# ATSAMRH71F20C register map
Vendor: Microchip Technology; Series: SAMRH71; File version: 0
CPU: CM7 r1p1, little endian, MPU, FPU, double-precision FPU, I-cache, D-cache, ITCM, DTCM, 3 interrupt priority bits, 75 interrupts
Registers are 32-bit, read-write, reset 0x0 unless marked. A register's access mark holds for its fields unless they carry their own. Offsets are from the block's base; [hi:lo] are bit positions; {n}, {i} and the like mark numbered series; 'fields as' and 'values as' point back to an identical list.

## HEMC
Base 0x40080000
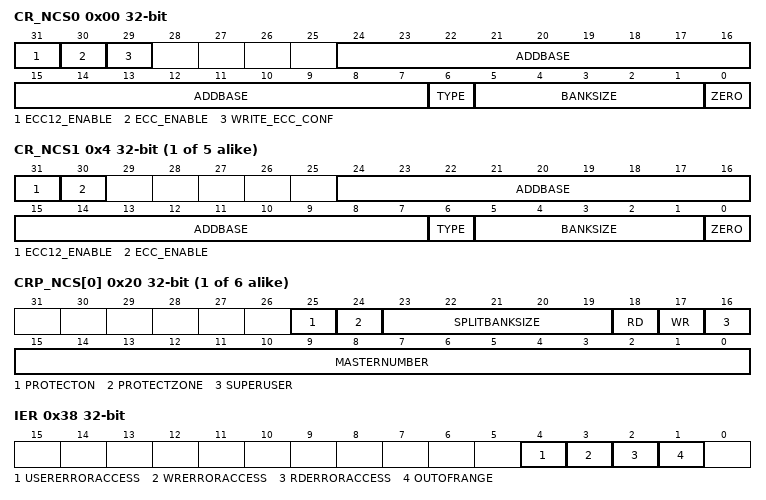
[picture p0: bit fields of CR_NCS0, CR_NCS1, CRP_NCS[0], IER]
0x00 CR_NCS0 — HEMC Control Register NCS 0
  [31] ECC12_ENABLE — BCH ECC Enable
  [30] ECC_ENABLE — ECC Protection Enable
  [29] WRITE_ECC_CONF — ECC Configuration Protection Enable
  [24:7] ADDBASE — relative base address of NCS area
  [6] TYPE — type of memory used
  [5:1] BANKSIZE
    0=_8KB (8Kbytes); 1=_16KB (16Kbytes); 2=_32KB (32Kbytes); 3=_64KB (64Kbytes); 4=_128KB (128Kbytes); 5=_256KB (256Kbytes); 6=_512KB (512Kbytes); 7=_1MB (1Mbytes); 8=_2MB (2Mbytes); 9=_4MB (4Mbytes); 10=_8MB (8Mbytes); 11=_16MB (16Mbytes); 12=_32MB (32Mbytes); 13=_64MB (64Mbytes); 14=_128MB (128Mbytes); 15=_256MB (256Mbytes (Default)); 16=_512MB (512Mbytes); 31=NOT_USED
  [0] ZERO — fixed to 0
{0x0+4i} CR_NCS{i} (i=1..5) — HEMC Control Register NCS {i}
  [31] ECC12_ENABLE — BCH ECC Enable
  [30] ECC_ENABLE — ECC Protection Enable
  [24:7] ADDBASE — relative base address of NCS area
  [6] TYPE — type of memory used
  [5:1] BANKSIZE
    values as CR_NCS0.BANKSIZE
  [0] ZERO — fixed to 0
0x18 CTRL — HEMC Polarity Control register
  [0] POL — External control buffer active polarity
{0x20+4i} CRP_NCS[{i}] (i=0..5) — HEMC Control Register Protection NCS
  [25] PROTECTON — protection activation
  [24] PROTECTZONE — select area protected
  [23:19] SPLITBANKSIZE — bank size internal separation
  [18] RD — Read Access
  [17] WR — Write Access
  [16] SUPERUSER — User or Superuser access
  [15:0] MASTERNUMBER — Master Number ID
0x38 IER wo — HEMC Interrupt Enable Register
  [4] USERERRORACCESS — user or superuser access error
  [3] WRERRORACCESS — write access error
  [2] RDERRORACCESS — read access error
  [1] OUTOFRANGE
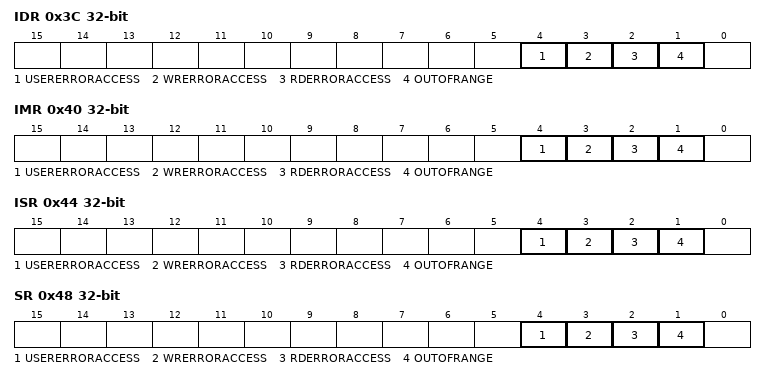
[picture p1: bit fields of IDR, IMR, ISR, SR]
0x3C IDR wo — HEMC Interrupt Disable Register
  fields as IER
0x40 IMR ro — HEMC Interrupt Mask Register
  fields as IER
0x44 ISR ro — HEMC Interrupt Status Register
  [4] USERERRORACCESS — User or SuperUser Error Access
  [3] WRERRORACCESS — Write access error
  [2] RDERRORACCESS — read access error
  [1] OUTOFRANGE
0x48 SR ro — HEMC Status Register
  [4] USERERRORACCESS — User or SuperUser Error Access
  [3] WRERRORACCESS — Write access error
  [2] RDERRORACCESS — Read access error
  [1] OUTOFRANGE
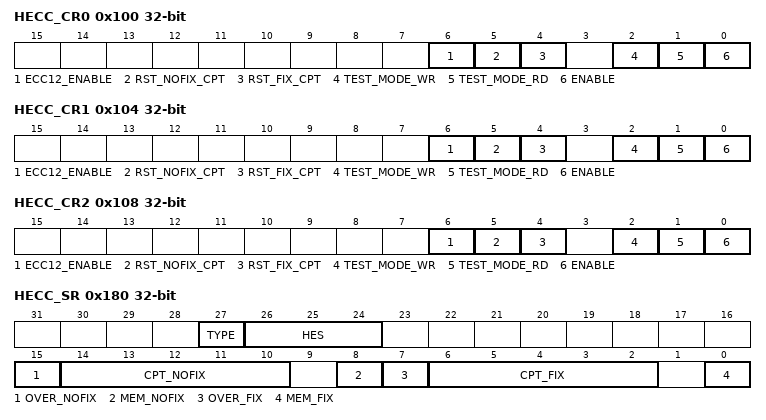
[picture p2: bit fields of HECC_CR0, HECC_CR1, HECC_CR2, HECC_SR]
0x100 HECC_CR0 — HECC Control Register Channel 0 (HSMC)
  [6] ECC12_ENABLE — BCH ECC enable
  [5] RST_NOFIX_CPT — reset the un-fixable error counter
  [4] RST_FIX_CPT — reset the fixable error counter
  [2] TEST_MODE_WR — test mode of ECC protection - write mode
  [1] TEST_MODE_RD — test mode of ECC protection - read mode
  [0] ENABLE — ECC protection enable
0x104 HECC_CR1 — HECC Control Register Channel 1 (HSDRAMC)
  fields as HECC_CR0
0x108 HECC_CR2 — HECC Control Register Channel 2 (HSDRAMC)
  fields as HECC_CR0
0x140 HECC_TESTCB0 — HECC Test mode Register Channel 0 (HSMC)
  [15:0] TCB1 — test check bit (16 bit)
0x144 HECC_TESTCB1 — HECC Test mode Register Channel 1 (HSDRAMC)
  [15:0] TCB1 — test check bit (16 bit)
0x148 HECC_TESTCB2 — HECC Test mode Register Channel 2 (HSDRAMC)
  [15:0] TCB1 — test check bit (16 bit)
0x180 HECC_SR ro — HECC Status Register
  [27] TYPE — write or read access
  [26:24] HES — Hardware Error Size
  [15] OVER_NOFIX — counter overflow
  [14:10] CPT_NOFIX — 5 bits counter
  [8] MEM_NOFIX — Un-fixable error status
  [7] OVER_FIX — counter overflow
  [6:2] CPT_FIX — 5 bits counter
  [0] MEM_FIX — Fixable error status
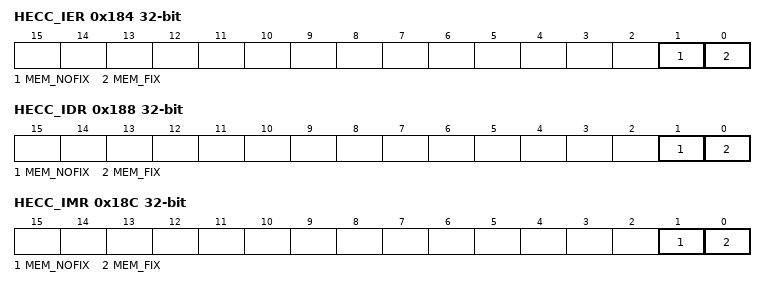
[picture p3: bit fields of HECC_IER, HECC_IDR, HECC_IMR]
0x184 HECC_IER wo — HECC Interrupt Enable Register
  [1] MEM_NOFIX — Un-fixable error
  [0] MEM_FIX — Fixable error
0x188 HECC_IDR wo — HECC Interrupt Disable Register
  [1] MEM_NOFIX — un-fixable error
  [0] MEM_FIX — fixable error
0x18C HECC_IMR ro — HECC Interrupt Mask Register
  [1] MEM_NOFIX — un-fixable error
  [0] MEM_FIX — fixable error
0x190 HECC_FAILAR ro — HECC Fail address register
  [31:0] ADDRESS — address of the error detected

## Notices in the file
Copyright (c) 2023 Microchip Technology Inc.
SPDX-License-Identifier: Apache-2.0
Licensed under the Apache License, Version 2.0 (the "License");
you may not use this file except in compliance with the License.
You may obtain a copy of the License at
http://www.apache.org/licenses/LICENSE-2.0
Unless required by applicable law or agreed to in writing, software
distributed under the License is distributed on an "AS IS" BASIS,
WITHOUT WARRANTIES OR CONDITIONS OF ANY KIND, either express or implied.
See the License for the specific language governing permissions and
limitations under the License.
